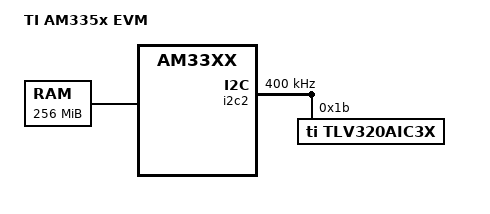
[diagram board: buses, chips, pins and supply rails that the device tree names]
/*
 * Copyright (C) 2012 Texas Instruments Incorporated - http://www.ti.com/
 *
 * This program is free software; you can redistribute it and/or modify
 * it under the terms of the GNU General Public License version 2 as
 * published by the Free Software Foundation.
 */
/dts-v1/;

/include/ "am33xx.dtsi"

/ {
	model = "TI AM335x EVM";
	compatible = "ti,am335x-evm", "ti,am33xx";

	memory {
		device_type = "memory";
		reg = <0x80000000 0x10000000>; /* 256 MB */
	};

	sound {
		compatible = "ti,davinci-evm-audio";
		ti,model = "AM335X EVM";
		ti,audio-codec = <&tlv320aic3x>;
		ti,mcasp-controller = <&mcasp1>;
		ti,codec-clock-rate = <12000000>;
		dai-data =
			"TLV320AIC3X", 		"AIC3X",
			"tlv320aic3x-hifi",	"true",
			"evm-ops";
		ti,audio-routing =
				"Headphone Jack",	"HPLOUT",
				"Headphone Jack",	"HPROUT",
				"Line Out",		"LLOUT",
				"Line Out",		"RLOUT",
				"MIC3L",		"Mic Bias 2V",
				"MIC3R",		"Mic Bias 2V",
				"Mic Bias 2V",		"Mic Jack",
				"LINE1L",		"Line In",
				"LINE2L",		"Line In",
				"LINE1R",		"Line In",
				"LINE2R",		"Line In";
	};

};

&mcasp1 {
	op-mode = <0>;		/* MCASP_IIS_MODE */
	tdm-slots = <2>;
	num-serializer = <16>;
	serial-dir = <	/* 0: INACTIVE, 1: TX, 2: RX */
			0 0 1 2
			0 0 0 0
			0 0 0 0
			0 0 0 0 >;
	tx-num-evt = <1>;
	rx-num-evt = <1>;
};

&i2c2 {
	clock-frequency = <400000>;

	tlv320aic3x: tlv320aic3x@1b {
		compatible = "ti,tlv320aic3x";
		reg = <0x1b>;
	};
};

&am3358_pinmux {
	pinctrl-names = "default";
	pinctrl-0 = <&evm_pins>;

	evm_pins: pinmux_evm_pins {
		pinctrl-single,pins = <
			/* I2C1 */
			0x158 0x62	/* spi0_d1.i2c1_sda,  MODE2 | INPUT | SLEWCTRL_SLOW */
			0x15c 0x62	/* spi0_cs0.i2c1_scl, MODE2 | INPUT | SLEWCTRL_SLOW */

			/* McASP1 */
			0x10c 0x24	/* mii1_crs.mcasp1_aclkx,	MODE4 | INPUT_PULLDOWN */
			0x110 0x24	/* mii1_rxerr.mcasp1_fsx,	MODE4 | INPUT_PULLDOWN */
			0x108 0x24	/* mii1_col.mcasp1_axr2,	MODE4 | INPUT_PULLDOWN */
			0x144 0x24	/* rmii1_refclk.mcasp1_axr3,	MODE4 | INPUT_PULLDOWN */

		>;
	};
};
